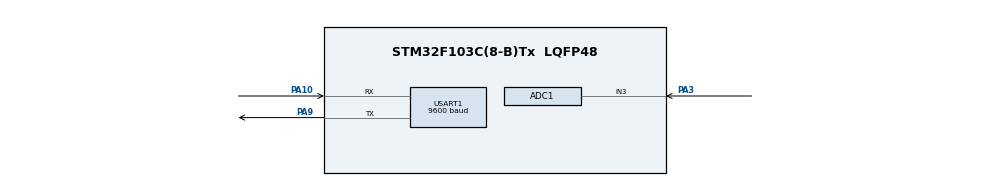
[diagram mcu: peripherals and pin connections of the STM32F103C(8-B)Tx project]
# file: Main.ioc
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ADC1.Channel-1\#ChannelRegularConversion=ADC_CHANNEL_3
ADC1.ContinuousConvMode=ENABLE
ADC1.NbrOfConversionFlag=1
ADC1.Rank-1\#ChannelRegularConversion=1
ADC1.SamplingTime-1\#ChannelRegularConversion=ADC_SAMPLETIME_1CYCLE_5
ADC1.master=1
Mcu.Family=STM32F1
Mcu.Name=STM32F103C(8-B)Tx
Mcu.Package=LQFP48
NVIC.PriorityGroup=NVIC_PRIORITYGROUP_4
PA10.Mode=Asynchronous
PA10.Signal=USART1_RX
PA13.Mode=Serial_Wire
PA13.Signal=SYS_JTMS-SWDIO
PA14.Mode=Serial_Wire
PA14.Signal=SYS_JTCK-SWCLK
PA3.Signal=ADCx_IN3
PA9.Mode=Asynchronous
PA9.Signal=USART1_TX
ProjectManager.HeapSize=0x200
ProjectManager.StackSize=0x400
ProjectManager.TargetToolchain=MDK-ARM V5.32
RCC.APB1Freq_Value=8000000
RCC.APB2Freq_Value=8000000
SH.ADCx_IN3.0=ADC1_IN3,IN3
USART1.BaudRate=9600
USART1.Mode=MODE_TX_RX
USART1.VirtualMode=VM_ASYNC
board=custom

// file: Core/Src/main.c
/* USER CODE BEGIN Header */
/**
  ******************************************************************************
  * @file           : main.c
  * @brief          : Main program body
  ******************************************************************************
  * @attention
  *
  * <h2><center>&copy; Copyright (c) 2021 STMicroelectronics.
  * All rights reserved.</center></h2>
  *
  * This software component is licensed by ST under BSD 3-Clause license,
  * the "License"; You may not use this file except in compliance with the
  * License. You may obtain a copy of the License at:
  *                        opensource.org/licenses/BSD-3-Clause
  *
  ******************************************************************************
  */
/* USER CODE END Header */
#include "main.h"

/* USER CODE BEGIN Includes */
#include "stdio.h"

/* USER CODE END Includes */

/* USER CODE BEGIN PV */
uint16_t adc_value;			//Define variable adc_value
/* USER CODE END PV */

void SystemClock_Config(void);
static void MX_GPIO_Init(void);
static void MX_ADC1_Init(void);
static void MX_ADC1_Init2(void);
static void MX_USART1_UART_Init(void);

int main(void)
{
  /* USER CODE BEGIN 1 */

float voltage;				//variable for representing voltage
uint8_t str[21];			//string for representing message
uint8_t i = 0;

  /* USER CODE END 1 */

  /* MCU Configuration--------------------------------------------------------*/

  /* Reset of all peripherals, Initializes the Flash interface and the Systick. */
  LL_APB2_GRP1_EnableClock(LL_APB2_GRP1_PERIPH_AFIO);
  LL_APB1_GRP1_EnableClock(LL_APB1_GRP1_PERIPH_PWR);

  /* System interrupt init*/
  NVIC_SetPriorityGrouping(NVIC_PRIORITYGROUP_4);

  /** NOJTAG: JTAG-DP Disabled and SW-DP Enabled
  */
  LL_GPIO_AF_Remap_SWJ_NOJTAG();

  /* Configure the system clock */
  SystemClock_Config();

  /* Initialize all configured peripherals */
  MX_GPIO_Init();
  MX_ADC1_Init();
  MX_USART1_UART_Init();
  /* USER CODE BEGIN 2 */

	LL_ADC_Enable(ADC1);						//Enable ADC1
	//LL_ADC_EnableIT_EOS(ADC1);					//Enable end of sequence interrupt for ADC1
	LL_ADC_DisableIT_EOS(ADC1);
	LL_ADC_StartCalibration(ADC1); 				//Calibration start
	while(LL_ADC_IsCalibrationOnGoing(ADC1))	//Wait till the calibration is finished
		__NOP();
	LL_ADC_REG_StartConversionSWStart(ADC1);	//Start the conversion
  /* USER CODE END 2 */

  /* Infinite loop */
  /* USER CODE BEGIN WHILE */
	LL_USART_TransmitData8(USART1, 13); LL_mDelay(1);
	LL_USART_TransmitData8(USART1, 10); LL_mDelay(1);

  while(1){
    /* USER CODE END WHILE */

    /* USER CODE BEGIN 3 */
    LL_ADC_REG_StartConversionSWStart(ADC1);
		while (!LL_ADC_IsActiveFlag_EOS(ADC1));
		/* representing the voltage in desired format */
		adc_value = LL_ADC_REG_ReadConversionData12(ADC1); //adc_value=4095;
		voltage = (float)(adc_value * 3.3) / (4095);
		sprintf((char*)str, "voltage is: %0.2f\r\n", voltage);
		for(i=0; i<19; i++){
			LL_USART_TransmitData8(USART1, str[i]);
			while(!LL_USART_IsActiveFlag_TXE(USART1));
		}
		i = 0;

		LL_mDelay(1000);
  }
  /* USER CODE END 3 */
}

void SystemClock_Config(void)
{
  LL_FLASH_SetLatency(LL_FLASH_LATENCY_0);
  while(LL_FLASH_GetLatency()!= LL_FLASH_LATENCY_0)
  {
  }
  LL_RCC_HSI_SetCalibTrimming(16);
  LL_RCC_HSI_Enable();

   /* Wait till HSI is ready */
  while(LL_RCC_HSI_IsReady() != 1)
  {

  }
  LL_RCC_SetAHBPrescaler(LL_RCC_SYSCLK_DIV_1);
  LL_RCC_SetAPB1Prescaler(LL_RCC_APB1_DIV_1);
  LL_RCC_SetAPB2Prescaler(LL_RCC_APB2_DIV_1);
  LL_RCC_SetSysClkSource(LL_RCC_SYS_CLKSOURCE_HSI);

   /* Wait till System clock is ready */
  while(LL_RCC_GetSysClkSource() != LL_RCC_SYS_CLKSOURCE_STATUS_HSI)
  {

  }
  LL_Init1msTick(8000000);
  LL_SetSystemCoreClock(8000000);
  LL_RCC_SetADCClockSource(LL_RCC_ADC_CLKSRC_PCLK2_DIV_2);
}

static void MX_ADC1_Init(void)
{

  LL_ADC_InitTypeDef ADC_InitStruct = {0};
  LL_ADC_CommonInitTypeDef ADC_CommonInitStruct = {0};
  LL_ADC_REG_InitTypeDef ADC_REG_InitStruct = {0};

  LL_GPIO_InitTypeDef GPIO_InitStruct = {0};

  /* Peripheral clock enable */
  LL_APB2_GRP1_EnableClock(LL_APB2_GRP1_PERIPH_ADC1);

  LL_APB2_GRP1_EnableClock(LL_APB2_GRP1_PERIPH_GPIOA);
  /**ADC1 GPIO Configuration
  PA3   ------> ADC1_IN3
  */
  GPIO_InitStruct.Pin = LL_GPIO_PIN_3;
  GPIO_InitStruct.Mode = LL_GPIO_MODE_ANALOG;
  LL_GPIO_Init(GPIOA, &GPIO_InitStruct);

  /** Common config
  */
  ADC_InitStruct.DataAlignment = LL_ADC_DATA_ALIGN_RIGHT;
  ADC_InitStruct.SequencersScanMode = LL_ADC_SEQ_SCAN_DISABLE;
  LL_ADC_Init(ADC1, &ADC_InitStruct);
  ADC_CommonInitStruct.Multimode = LL_ADC_MULTI_INDEPENDENT;
  LL_ADC_CommonInit(__LL_ADC_COMMON_INSTANCE(ADC1), &ADC_CommonInitStruct);
  ADC_REG_InitStruct.TriggerSource = LL_ADC_REG_TRIG_SOFTWARE;
  ADC_REG_InitStruct.SequencerLength = LL_ADC_REG_SEQ_SCAN_DISABLE;
  ADC_REG_InitStruct.SequencerDiscont = LL_ADC_REG_SEQ_DISCONT_DISABLE;
  ADC_REG_InitStruct.ContinuousMode = LL_ADC_REG_CONV_SINGLE;
  ADC_REG_InitStruct.DMATransfer = LL_ADC_REG_DMA_TRANSFER_NONE;
  LL_ADC_REG_Init(ADC1, &ADC_REG_InitStruct);

  /** Configure Regular Channel
  */
  LL_ADC_REG_SetSequencerRanks(ADC1, LL_ADC_REG_RANK_1, LL_ADC_CHANNEL_3);
  LL_ADC_SetChannelSamplingTime(ADC1, LL_ADC_CHANNEL_3, LL_ADC_SAMPLINGTIME_1CYCLE_5);

}

static void MX_USART1_UART_Init(void)
{

  LL_USART_InitTypeDef USART_InitStruct = {0};

  LL_GPIO_InitTypeDef GPIO_InitStruct = {0};

  /* Peripheral clock enable */
  LL_APB2_GRP1_EnableClock(LL_APB2_GRP1_PERIPH_USART1);

  LL_APB2_GRP1_EnableClock(LL_APB2_GRP1_PERIPH_GPIOA);
  /**USART1 GPIO Configuration
  PA9   ------> USART1_TX
  PA10   ------> USART1_RX
  */
  GPIO_InitStruct.Pin = LL_GPIO_PIN_9;
  GPIO_InitStruct.Mode = LL_GPIO_MODE_ALTERNATE;
  GPIO_InitStruct.Speed = LL_GPIO_SPEED_FREQ_HIGH;
  GPIO_InitStruct.OutputType = LL_GPIO_OUTPUT_PUSHPULL;
  LL_GPIO_Init(GPIOA, &GPIO_InitStruct);

  GPIO_InitStruct.Pin = LL_GPIO_PIN_10;
  GPIO_InitStruct.Mode = LL_GPIO_MODE_FLOATING;
  LL_GPIO_Init(GPIOA, &GPIO_InitStruct);

  USART_InitStruct.BaudRate = 9600;
  USART_InitStruct.DataWidth = LL_USART_DATAWIDTH_8B;
  USART_InitStruct.StopBits = LL_USART_STOPBITS_1;
  USART_InitStruct.Parity = LL_USART_PARITY_NONE;
  USART_InitStruct.TransferDirection = LL_USART_DIRECTION_TX_RX;
  USART_InitStruct.HardwareFlowControl = LL_USART_HWCONTROL_NONE;
  USART_InitStruct.OverSampling = LL_USART_OVERSAMPLING_16;
  LL_USART_Init(USART1, &USART_InitStruct);
  LL_USART_ConfigAsyncMode(USART1);
  LL_USART_Enable(USART1);

}

static void MX_GPIO_Init(void)
{

  /* GPIO Ports Clock Enable */
  LL_APB2_GRP1_EnableClock(LL_APB2_GRP1_PERIPH_GPIOA);

}

/* USER CODE BEGIN 4 */
static void MX_ADC1_Init2(void){
    LL_APB2_GRP1_EnableClock(LL_APB2_GRP1_PERIPH_ADC1);
    LL_ADC_SetDataAlignment(ADC1, LL_ADC_DATA_ALIGN_RIGHT);
    LL_ADC_SetSequencersScanMode(ADC1, LL_ADC_SEQ_SCAN_DISABLE);
    LL_ADC_REG_SetTriggerSource(ADC1, LL_ADC_REG_TRIG_SOFTWARE);
    LL_ADC_REG_SetContinuousMode(ADC1, LL_ADC_REG_CONV_SINGLE);
    LL_ADC_SetChannelSamplingTime(ADC1, LL_ADC_CHANNEL_3, LL_ADC_SAMPLINGTIME_28CYCLES_5);
    LL_ADC_REG_SetSequencerRanks(ADC1, LL_ADC_REG_RANK_1, LL_ADC_CHANNEL_3);

    // Enable ADC
    LL_ADC_Enable(ADC1);
    LL_mDelay(1);  // Delay for ADC stabilization
}
/* USER CODE END 4 */

void Error_Handler(void)
{
}
